AUTOSAR XML (schema 4-0-3)
standard types defined: Boolean, UInt16, UInt32, UInt8
package /AUTOSAR_Platform/DataConstrs
  range DC_Boolean: raw 0..1
  range DC_UInt16: raw 0..65535
  range DC_UInt8: raw 0..255
package /PATAC/MSM/ComponentTypes
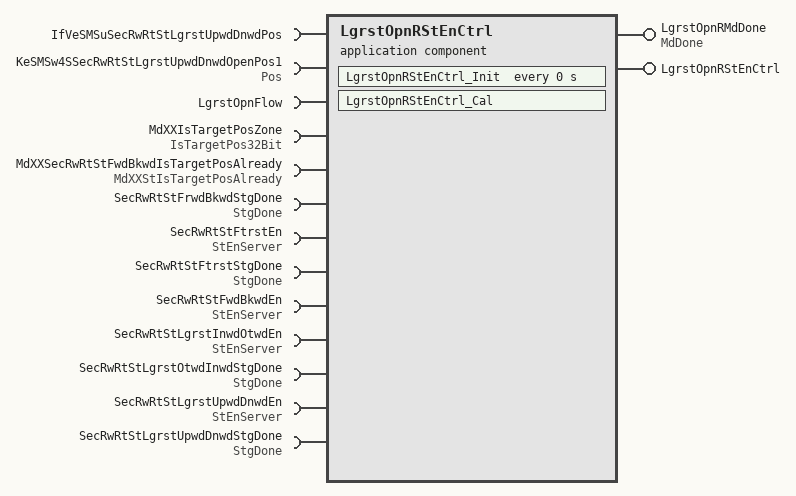
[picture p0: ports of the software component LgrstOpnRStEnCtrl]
  application sw component type LgrstOpnRStEnCtrl
    provide port LgrstOpnRMdDone: nonqueued-sender-com-spec{data-element=MdDone/Val, init-value=0}, provided-interface=MdDone
    provide port LgrstOpnRStEnCtrl: server-com-spec{operation=LgrstOpnRStEnCtrl/Cal, queue-length=1}, provided-interface=LgrstOpnRStEnCtrl
    13 x require port:
      IfVeSMSuSecRwRtStLgrstUpwdDnwdPos: nonqueued-receiver-com-spec{data-element=IfVeSMSuSecRwRtStLgrstUpwdDnwdPos/Val, filter=data-filter-type=ALWAYS, init-value=0}, required-interface=IfVeSMSuSecRwRtStLgrstUpwdDnwdPos
      KeSMSw4SSecRwRtStLgrstUpwdDnwdOpenPos1: parameter-require-com-spec{init-value=0, parameter=Val}, required-interface=Pos
      LgrstOpnFlow: client-com-spec=LgrstOpnFlow/Cal, required-interface=LgrstOpnFlow
      MdXXIsTargetPosZone: nonqueued-receiver-com-spec{data-element=IsTargetPos32Bit/Val, filter=data-filter-type=ALWAYS, init-value=0}, required-interface=IsTargetPos32Bit
      MdXXSecRwRtStFwdBkwdIsTargetPosAlready: nonqueued-receiver-com-spec{data-element=MdXXStIsTargetPosAlready/Val, filter=data-filter-type=ALWAYS, init-value=0}, required-interface=MdXXStIsTargetPosAlready
      SecRwRtStFrwdBkwdStgDone: nonqueued-receiver-com-spec{data-element=StgDone/Val, filter=data-filter-type=ALWAYS, init-value=0}, required-interface=StgDone
      SecRwRtStFtrstEn: required-com-specs=[Clear, Get, Set], required-interface=StEnServer
      SecRwRtStFtrstStgDone: nonqueued-receiver-com-spec{data-element=StgDone/Val, filter=data-filter-type=ALWAYS, init-value=0}, required-interface=StgDone
      SecRwRtStFwdBkwdEn: required-com-specs=[Clear, Get, Set], required-interface=StEnServer
      SecRwRtStLgrstInwdOtwdEn: required-com-specs=[Clear, Get, Set], required-interface=StEnServer
      SecRwRtStLgrstOtwdInwdStgDone: nonqueued-receiver-com-spec{data-element=StgDone/Val, filter=data-filter-type=ALWAYS, init-value=0}, required-interface=StgDone
      SecRwRtStLgrstUpwdDnwdEn: required-com-specs=[Clear, Get, Set], required-interface=StEnServer
      SecRwRtStLgrstUpwdDnwdStgDone: nonqueued-receiver-com-spec{data-element=StgDone/Val, filter=data-filter-type=ALWAYS, init-value=0}, required-interface=StgDone
    behavior LgrstOpnRStEnCtrl_InternalBehavior
      operation invoked event OIT_LgrstOpnRStEnCtrl_Cal_LgrstOpnRStEnCtrl_Cal: start-on-event=LgrstOpnRStEnCtrl_Cal, operation=LgrstOpnRStEnCtrl.Cal
      timing event LgrstOpnRStEnCtrl_InitEvent: start-on-event=LgrstOpnRStEnCtrl_Init, period=0
      runnable LgrstOpnRStEnCtrl_Cal
        data-receive-point-by-arguments:
          7 x access:
            REC_IfVeSMSuSecRwRtStLgrstUpwdDnwdPos_Val: accessed-variable=IfVeSMSuSecRwRtStLgrstUpwdDnwdPos.Val
            REC_MdXXIsTargetPosZone_Val: accessed-variable=MdXXIsTargetPosZone.Val
            REC_MdXXSecRwRtStFwdBkwdIsTargetPosAlready_Val: accessed-variable=MdXXSecRwRtStFwdBkwdIsTargetPosAlready.Val
            REC_SecRwRtStFrwdBkwdStgDone_Val: accessed-variable=SecRwRtStFrwdBkwdStgDone.Val
            REC_SecRwRtStFtrstStgDone_Val: accessed-variable=SecRwRtStFtrstStgDone.Val
            REC_SecRwRtStLgrstOtwdInwdStgDone_Val: accessed-variable=SecRwRtStLgrstOtwdInwdStgDone.Val
            REC_SecRwRtStLgrstUpwdDnwdStgDone_Val: accessed-variable=SecRwRtStLgrstUpwdDnwdStgDone.Val
        data-send-points:
          access SEND_LgrstOpnRMdDone_Val: accessed-variable=LgrstOpnRMdDone.Val
        parameter access PA_KeSMSw4SSecRwRtStLgrstUpwdDnwdOpenPos1_Val: accessed-parameter=KeSMSw4SSecRwRtStLgrstUpwdDnwdOpenPos1.Val
        9 x sync call, all with timeout=0:
          SC_LgrstOpnFlow_Cal: operation=LgrstOpnFlow.Cal
          SC_SecRwRtStFtrstEn_Clear: operation=SecRwRtStFtrstEn.Clear
          SC_SecRwRtStFtrstEn_Set: operation=SecRwRtStFtrstEn.Set
          SC_SecRwRtStFwdBkwdEn_Clear: operation=SecRwRtStFwdBkwdEn.Clear
          SC_SecRwRtStFwdBkwdEn_Set: operation=SecRwRtStFwdBkwdEn.Set
          SC_SecRwRtStLgrstInwdOtwdEn_Clear: operation=SecRwRtStLgrstInwdOtwdEn.Clear
          SC_SecRwRtStLgrstInwdOtwdEn_Set: operation=SecRwRtStLgrstInwdOtwdEn.Set
          SC_SecRwRtStLgrstUpwdDnwdEn_Clear: operation=SecRwRtStLgrstUpwdDnwdEn.Clear
          SC_SecRwRtStLgrstUpwdDnwdEn_Set: operation=SecRwRtStLgrstUpwdDnwdEn.Set
      runnable LgrstOpnRStEnCtrl_Init
        parameter access PA_KeSMSw4SSecRwRtStLgrstUpwdDnwdOpenPos1_Val: accessed-parameter=KeSMSw4SSecRwRtStLgrstUpwdDnwdOpenPos1.Val
  swc implementation LgrstOpnRStEnCtrl_Implementation: behavior=LgrstOpnRStEnCtrl_InternalBehavior
    code-descriptors:
      code Default: artifact-descriptors=autosar-engineering-object={short-label=Default, category=SWSRC}
package /PATAC/MSM/ModeAdjust/CalPortInterface
  parameter interface Pos
    parameter data prototype Val: sw-calibration-access=READ-WRITE, type=UInt16
package /PATAC/MSM/ModeAdjust/PortInterface
  client server interface LgrstOpnFlow
    operation Cal
      9 x arg, all with server-argument-impl-policy=USE-ARGUMENT-TYPE:
        LgrstUpwdDnwdPos: type=UInt16, direction=IN
        LgrstUpwdDnwdOpenPos1: type=UInt16, direction=IN
        LgrstUpwdStgDone: type=Boolean, direction=IN
        FtrstStgDone: type=Boolean, direction=IN
        LgrstInwdStgDone: type=Boolean, direction=IN
        Failflg: type=Boolean, direction=OUT
        LgrstInwdOtwdEn: type=Boolean, direction=OUT
        LgrstUpwdDnwdEn: type=Boolean, direction=OUT
        FtrstEn: type=Boolean, direction=OUT
  client server interface LgrstOpnRStEnCtrl
    operation Cal
  client server interface StEnServer
    operation Clear
      arg data: type=UInt8, direction=IN, server-argument-impl-policy=USE-ARGUMENT-TYPE
    operation Get
      arg data: type=UInt32, direction=OUT, server-argument-impl-policy=USE-ARGUMENT-TYPE
    operation Set
      arg data: type=UInt8, direction=IN, server-argument-impl-policy=USE-ARGUMENT-TYPE
  4 x sender receiver interface:
    IsTargetPos32Bit: invalidation-policy{data-element=IsTargetPos32Bit/Val, handle-invalid=DONT-INVALIDATE}
      data Val: type=UInt32
    MdDone: invalidation-policy{data-element=MdDone/Val, handle-invalid=DONT-INVALIDATE}
      data Val: type=UInt8
    MdXXStIsTargetPosAlready: invalidation-policy{data-element=MdXXStIsTargetPosAlready/Val, handle-invalid=DONT-INVALIDATE}
      data Val: type=UInt32
    StgDone: invalidation-policy{data-element=StgDone/Val, handle-invalid=DONT-INVALIDATE}
      data Val: type=Boolean
package /PATAC/MSM/PortInterfaces
  sender receiver interface IfVeSMSuSecRwRtStLgrstUpwdDnwdPos: invalidation-policy{data-element=IfVeSMSuSecRwRtStLgrstUpwdDnwdPos/Val, handle-invalid=DONT-INVALIDATE}
    data Val: type=UInt16
